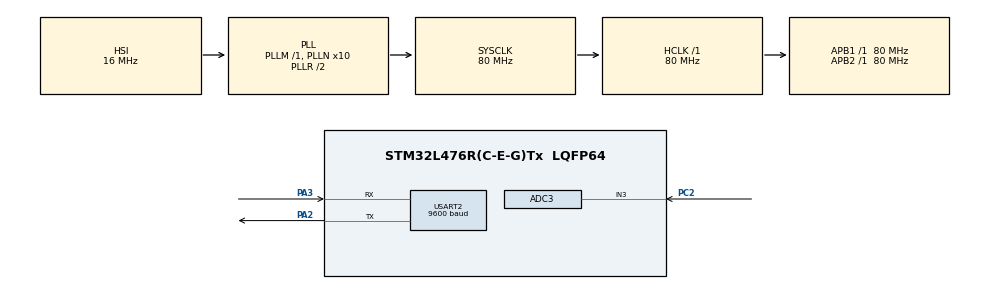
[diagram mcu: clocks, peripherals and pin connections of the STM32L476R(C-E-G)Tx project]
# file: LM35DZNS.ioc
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ADC3.Channel-0\#ChannelRegularConversion=ADC_CHANNEL_3
ADC3.NbrOfConversionFlag=1
ADC3.OffsetNumber-0\#ChannelRegularConversion=ADC_OFFSET_NONE
ADC3.Overrun=ADC_OVR_DATA_OVERWRITTEN
ADC3.Rank-0\#ChannelRegularConversion=1
ADC3.SamplingTime-0\#ChannelRegularConversion=ADC_SAMPLETIME_2CYCLES_5
Mcu.Family=STM32L4
Mcu.Name=STM32L476R(C-E-G)Tx
Mcu.Package=LQFP64
NVIC.ADC3_IRQn=true\:0\:0\:false\:false\:true\:true\:true\:true
NVIC.PriorityGroup=NVIC_PRIORITYGROUP_4
PA2.Mode=Asynchronous
PA2.Signal=USART2_TX
PA3.Mode=Asynchronous
PA3.Signal=USART2_RX
PC2.Signal=ADCx_IN3
ProjectManager.HeapSize=0x200
ProjectManager.StackSize=0x400
ProjectManager.TargetToolchain=STM32CubeIDE
RCC.ADCFreq_Value=64000000
RCC.AHBFreq_Value=80000000
RCC.APB1Freq_Value=80000000
RCC.APB1TimFreq_Value=80000000
RCC.APB2Freq_Value=80000000
RCC.APB2TimFreq_Value=80000000
RCC.CortexFreq_Value=80000000
RCC.HCLKFreq_Value=80000000
RCC.HSE_VALUE=8000000
RCC.HSI_VALUE=16000000
RCC.LSE_VALUE=32768
RCC.MSI_VALUE=4000000
RCC.PLLN=10
RCC.PLLSourceVirtual=RCC_PLLSOURCE_HSI
RCC.SYSCLKFreq_VALUE=80000000
RCC.SYSCLKSource=RCC_SYSCLKSOURCE_PLLCLK
RCC.USBFreq_Value=64000000
RCC.VCOOutputFreq_Value=160000000
SH.ADCx_IN3.0=ADC3_IN3,IN3-Single-Ended
USART2.BaudRate=9600
USART2.VirtualMode-Asynchronous=VM_ASYNC
board=custom

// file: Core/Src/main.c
/* USER CODE BEGIN Header */
/**
  ******************************************************************************
  * @file           : main.c
  * @brief          : Main program body
  ******************************************************************************
  * @attention
  *
  * Copyright (c) 2024 STMicroelectronics.
  * All rights reserved.
  *
  * This software is licensed under terms that can be found in the LICENSE file
  * in the root directory of this software component.
  * If no LICENSE file comes with this software, it is provided AS-IS.
  *
  ******************************************************************************
  */
/* USER CODE END Header */
#include "main.h"

/* USER CODE BEGIN Includes */
#include <stdio.h>
#include <string.h>
/* USER CODE END Includes */

ADC_HandleTypeDef hadc3;

UART_HandleTypeDef huart2;

/* USER CODE BEGIN PV */
float Temperatura;
char send[20];
uint32_t adcResult;
/* USER CODE END PV */

void SystemClock_Config(void);
static void MX_GPIO_Init(void);
static void MX_ADC3_Init(void);
static void MX_USART2_UART_Init(void);

int main(void)
{

  /* MCU Configuration--------------------------------------------------------*/

  /* Reset of all peripherals, Initializes the Flash interface and the Systick. */
  HAL_Init();

  /* Configure the system clock */
  SystemClock_Config();

  /* Initialize all configured peripherals */
  MX_GPIO_Init();
  MX_ADC3_Init();
  MX_USART2_UART_Init();
  /* USER CODE BEGIN 2 */
HAL_ADC_Start(&hadc3);
  /* USER CODE END 2 */

  /* Infinite loop */
  /* USER CODE BEGIN WHILE */
  while (1)
  {
	  HAL_ADC_PollForConversion(&hadc3, 100);
	  adcResult =HAL_ADC_GetValue(&hadc3);
	  Temperatura =((float)adcResult)*3300.0/4095.0;
	  sprintf(send,"Analog Volt: %f",Temperatura);
	  HAL_UART_Transmit(&huart2, send, strlen(send), HAL_MAX_DELAY);
	  Temperatura=Temperatura/10.0;
	  sprintf(send,"Temperatura: %f\r\n",Temperatura);
	  HAL_UART_Transmit(&huart2, send, strlen(send), HAL_MAX_DELAY);
	  HAL_Delay(500);
	  HAL_ADC_Start(&hadc3);
    /* USER CODE END WHILE */

  }
}

void SystemClock_Config(void)
{
  RCC_OscInitTypeDef RCC_OscInitStruct = {0};
  RCC_ClkInitTypeDef RCC_ClkInitStruct = {0};

  /** Configure the main internal regulator output voltage
  */
  if (HAL_PWREx_ControlVoltageScaling(PWR_REGULATOR_VOLTAGE_SCALE1) != HAL_OK)
  {
    Error_Handler();
  }

  /** Initializes the RCC Oscillators according to the specified parameters
  * in the RCC_OscInitTypeDef structure.
  */
  RCC_OscInitStruct.OscillatorType = RCC_OSCILLATORTYPE_HSI;
  RCC_OscInitStruct.HSIState = RCC_HSI_ON;
  RCC_OscInitStruct.HSICalibrationValue = RCC_HSICALIBRATION_DEFAULT;
  RCC_OscInitStruct.PLL.PLLState = RCC_PLL_ON;
  RCC_OscInitStruct.PLL.PLLSource = RCC_PLLSOURCE_HSI;
  RCC_OscInitStruct.PLL.PLLM = 1;
  RCC_OscInitStruct.PLL.PLLN = 10;
  RCC_OscInitStruct.PLL.PLLP = RCC_PLLP_DIV7;
  RCC_OscInitStruct.PLL.PLLQ = RCC_PLLQ_DIV2;
  RCC_OscInitStruct.PLL.PLLR = RCC_PLLR_DIV2;
  if (HAL_RCC_OscConfig(&RCC_OscInitStruct) != HAL_OK)
  {
    Error_Handler();
  }

  /** Initializes the CPU, AHB and APB buses clocks
  */
  RCC_ClkInitStruct.ClockType = RCC_CLOCKTYPE_HCLK|RCC_CLOCKTYPE_SYSCLK
                              |RCC_CLOCKTYPE_PCLK1|RCC_CLOCKTYPE_PCLK2;
  RCC_ClkInitStruct.SYSCLKSource = RCC_SYSCLKSOURCE_PLLCLK;
  RCC_ClkInitStruct.AHBCLKDivider = RCC_SYSCLK_DIV1;
  RCC_ClkInitStruct.APB1CLKDivider = RCC_HCLK_DIV1;
  RCC_ClkInitStruct.APB2CLKDivider = RCC_HCLK_DIV1;

  if (HAL_RCC_ClockConfig(&RCC_ClkInitStruct, FLASH_LATENCY_4) != HAL_OK)
  {
    Error_Handler();
  }
}

static void MX_ADC3_Init(void)
{

  ADC_ChannelConfTypeDef sConfig = {0};

  /** Common config
  */
  hadc3.Instance = ADC3;
  hadc3.Init.ClockPrescaler = ADC_CLOCK_ASYNC_DIV1;
  hadc3.Init.Resolution = ADC_RESOLUTION_12B;
  hadc3.Init.DataAlign = ADC_DATAALIGN_RIGHT;
  hadc3.Init.ScanConvMode = ADC_SCAN_DISABLE;
  hadc3.Init.EOCSelection = ADC_EOC_SINGLE_CONV;
  hadc3.Init.LowPowerAutoWait = DISABLE;
  hadc3.Init.ContinuousConvMode = DISABLE;
  hadc3.Init.NbrOfConversion = 1;
  hadc3.Init.DiscontinuousConvMode = DISABLE;
  hadc3.Init.ExternalTrigConv = ADC_SOFTWARE_START;
  hadc3.Init.ExternalTrigConvEdge = ADC_EXTERNALTRIGCONVEDGE_NONE;
  hadc3.Init.DMAContinuousRequests = DISABLE;
  hadc3.Init.Overrun = ADC_OVR_DATA_OVERWRITTEN;
  hadc3.Init.OversamplingMode = DISABLE;
  if (HAL_ADC_Init(&hadc3) != HAL_OK)
  {
    Error_Handler();
  }

  /** Configure Regular Channel
  */
  sConfig.Channel = ADC_CHANNEL_3;
  sConfig.Rank = ADC_REGULAR_RANK_1;
  sConfig.SamplingTime = ADC_SAMPLETIME_2CYCLES_5;
  sConfig.SingleDiff = ADC_SINGLE_ENDED;
  sConfig.OffsetNumber = ADC_OFFSET_NONE;
  sConfig.Offset = 0;
  if (HAL_ADC_ConfigChannel(&hadc3, &sConfig) != HAL_OK)
  {
    Error_Handler();
  }

}

static void MX_USART2_UART_Init(void)
{

  huart2.Instance = USART2;
  huart2.Init.BaudRate = 9600;
  huart2.Init.WordLength = UART_WORDLENGTH_8B;
  huart2.Init.StopBits = UART_STOPBITS_1;
  huart2.Init.Parity = UART_PARITY_NONE;
  huart2.Init.Mode = UART_MODE_TX_RX;
  huart2.Init.HwFlowCtl = UART_HWCONTROL_NONE;
  huart2.Init.OverSampling = UART_OVERSAMPLING_16;
  huart2.Init.OneBitSampling = UART_ONE_BIT_SAMPLE_DISABLE;
  huart2.AdvancedInit.AdvFeatureInit = UART_ADVFEATURE_NO_INIT;
  if (HAL_UART_Init(&huart2) != HAL_OK)
  {
    Error_Handler();
  }

}

static void MX_GPIO_Init(void)
{

  /* GPIO Ports Clock Enable */
  __HAL_RCC_GPIOC_CLK_ENABLE();
  __HAL_RCC_GPIOA_CLK_ENABLE();

}

void Error_Handler(void)
{
  __disable_irq();
  while (1)
  {
  }
}
